# FRI_1.0 register map
Vendor: Texas Instruments
Peripheral module from a debugger description file (folder mspm33c321x).
Registers are 32-bit, read-write, no defined reset value unless marked. A register's access mark holds for its fields unless they carry their own. Offsets are as the file gives them; lines under a group give offsets from that group; [hi:lo] are bit positions; {n}, {i} and the like mark numbered series; 'fields as' and 'values as' point back to an identical list; <NAME> marks a mode.

## FRI
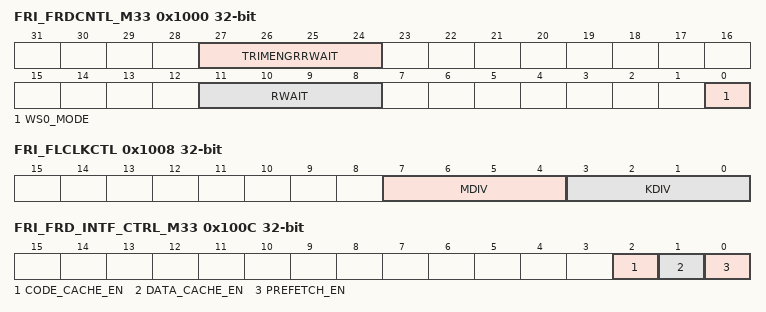
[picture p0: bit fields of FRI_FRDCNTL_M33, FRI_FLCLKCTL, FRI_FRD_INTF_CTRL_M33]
0x1000 FRI_FRDCNTL_M33 — Flash Read Control Register
  [27:24] TRIMENGRRWAIT — Random read waitstate of Trim and ENGR sectors #br# #br#These bits indicate how many waitstates are added to a flash read/fetch access. The TRIMENGRRWAIT value can be set anywhere from 0 to 0xF. For a flash access from TRIM or ENGR sectors, data is returned in RWAIT+1 SYSCLK cycles. #br#Note: The required wait states for each SYSCLK frequency can be found in the device data manual.
  [11:8] RWAIT — Random read waitstate #br# #br#These bits indicate how many waitstates are added to a flash read/fetch access. The RWAIT value can be set anywhere from 0 to 0xF. For a flash access, data is returned in RWAIT+1 SYSCLK cycles. #br#Note: The required wait states for each SYSCLK frequency can be found in the device data manual.
  [0] WS0_MODE — When set, waitstate of the flash will be forced to 0 Waitstate. #br#When this bit is set, RWAIT and TRIMENGRRWAIT values will be ignored.
0x1004 FRI_FLPROT — Flash program/erase protect register
  [0] FLWEPROT — Flash program/erase protect bit. #br#0 : Program erase operation allowed subject to security settings. #br#1 : Program erase operation blocked in hardware.
0x1008 FRI_FLCLKCTL — Flash NW clock control register.
  [7:4] MDIV — FCLKfrequency = (SYSCLKfrequency) / (KDIV/MDIV) #br#MDIV encoding: #br#0x0 : = 1 #br#0x1 : = 2 #br#0x2 : = 3 #br#0x3 : = 4 #br#0x4 : = 5 #br#0x5 - 0xF : = 6 #br# #br#Note: MDIV value should be less than or equal to KDIV value.
  [3:0] KDIV — FCLKfrequency = (SYSCLKfrequency) / (KDIV/MDIV) #br#KDIV encoding: #br#0x0 : = 1 #br#0x1 : = 2 #br#0x2 : = 3 #br#0x3 : = 4 #br#0x4 : = 5 #br#0x5 : = 6 #br#0x6 : = 10 #br#0x7 : = 12 #br#0x8 : = 15 #br#0x9 : = 20 #br#0xA : = 30 #br#0xB : = 60 #br#0xC - 0xF : = 30 #br# #br#Note: KDIV value should be less than or equal to KDIV value.
0x100C FRI_FRD_INTF_CTRL_M33 — Flash Read Interface Control Register
  [2] CODE_CACHE_EN — Code cache enable. #br#0 A value of 0 disables the Code cache. #br#1 A value of 1 enables the Code cache.
  [1] DATA_CACHE_EN — Data cache enable. #br#0 A value of 0 disables the data cache. #br#1 A value of 1 enables the data cache.
  [0] PREFETCH_EN — Prefetch enable. #br# 0 A value of 0 disables prefetch mechanism. #br#1 A value of 1 enables pre-fetch mechanism.
0x1010 FRI_DTB_MUXSEL — Flash Read Interface DTB Mux select
  [1:0] DTB_MUX_SEL_FRI — DTB Mux Select for Flash read interface signals to be exported out on DTB bus. Based on the MUXSELECT value, corresponding banks' DTB signals will be exported out. #br#00 - Bank0 #br#01 - Bank1 #br#10 - Bank2 #br#11 - Reserved
0x1100 FRI_ECC_ENABLE — ECC Enable
  [3:0] ENABLE — ECC enable. A value of 0xA would enable ECC. Any other value would disable ECC.
0x1104 FRI_FECC_CTRL_TOPOARIA — ECC Control
  [1:0] ECC_TEST_EN — ECC test mode enable. #br#00 ECC test mode disabled #br#01 ECC test mode enabled, one of the 64 data bits is flipped and fed to the redundant ECC logic (on both ECC logic low and ECC logc high blocks). #br#11 ECC test mode enabled, Two of the 64 data bits are flipped and fed to the redundant ECC logic (on both ECC logic low and ECC logc high blocks). #br#10 Reserved
